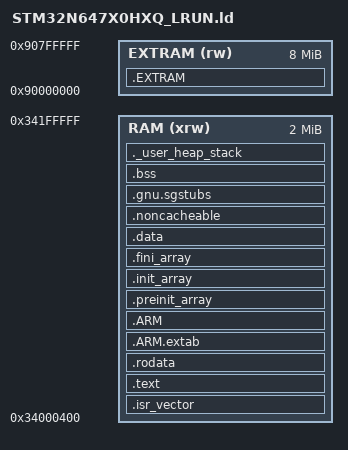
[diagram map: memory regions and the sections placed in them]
/*
******************************************************************************
** @file        : STM32N647X0HXQ_LRUN.ld
** @brief       : Linker script for STM32N647 - LRUN with HyperRAM (XSPI1)
**                Code in internal RAM, framebuffer in HyperRAM
******************************************************************************
*/

/* Entry Point */
ENTRY(Reset_Handler)

/* Highest address of the user mode stack */
_estack = ORIGIN(RAM) + LENGTH(RAM);
_sstack = _estack - _Min_Stack_Size;

_Min_Heap_Size = 0x200;
_Min_Stack_Size = 0x800;

/* Memories definition */
MEMORY
{
  RAM    (xrw)    : ORIGIN = 0x34000400,   LENGTH = 2047K
  EXTRAM (rw)     : ORIGIN = 0x90000000,   LENGTH = 8M
}

/* Sections */
SECTIONS
{
  .isr_vector :
  {
    . = ALIGN(4);
    KEEP(*(.isr_vector))
    . = ALIGN(4);
  } >RAM

  .text :
  {
    . = ALIGN(4);
    *(.text)
    *(.text*)
    *(.glue_7)
    *(.glue_7t)
    *(.eh_frame)
    *(.RamFunc)
    *(.RamFunc*)

    KEEP (*(.init))
    KEEP (*(.fini))

    . = ALIGN(4);
    _etext = .;
  } >RAM

  .rodata :
  {
    . = ALIGN(4);
    *(.rodata)
    *(.rodata*)
    . = ALIGN(4);
  } >RAM

  .ARM.extab   (READONLY) :
  {
    . = ALIGN(4);
    *(.ARM.extab* .gnu.linkonce.armextab.*)
    . = ALIGN(4);
  } >RAM

  .ARM (READONLY) :
  {
    . = ALIGN(4);
    __exidx_start = .;
    *(.ARM.exidx*)
    __exidx_end = .;
    . = ALIGN(4);
  } >RAM

  .preinit_array (READONLY) :
  {
    . = ALIGN(4);
    PROVIDE_HIDDEN (__preinit_array_start = .);
    KEEP (*(.preinit_array*))
    PROVIDE_HIDDEN (__preinit_array_end = .);
    . = ALIGN(4);
  } >RAM

  .init_array (READONLY) :
  {
    . = ALIGN(4);
    PROVIDE_HIDDEN (__init_array_start = .);
    KEEP (*(SORT(.init_array.*)))
    KEEP (*(.init_array*))
    PROVIDE_HIDDEN (__init_array_end = .);
    . = ALIGN(4);
  } >RAM

  .fini_array (READONLY) :
  {
    . = ALIGN(4);
    PROVIDE_HIDDEN (__fini_array_start = .);
    KEEP (*(SORT(.fini_array.*)))
    KEEP (*(.fini_array*))
    PROVIDE_HIDDEN (__fini_array_end = .);
    . = ALIGN(4);
  } >RAM

  _sidata = LOADADDR(.data);

  .data :
  {
    . = ALIGN(4);
    _sdata = .;
    *(.data)
    *(.data*)
    . = ALIGN(4);
    _edata = .;
  } >RAM

  .noncacheable :
  {
    . = ALIGN(8);
    __snoncacheable = .;
    KEEP(*(.noncacheable))
    . = ALIGN(8);
    __enoncacheable = .;
  } > RAM

  .gnu.sgstubs :
  {
    . = ALIGN(4);
    *(.gnu.sgstubs*)
    . = ALIGN(4);
  } >RAM

  . = ALIGN(4);
  .bss :
  {
    _sbss = .;
    __bss_start__ = _sbss;
    *(.bss)
    *(.bss*)
    *(COMMON)
    . = ALIGN(4);
    _ebss = .;
    __bss_end__ = _ebss;
  } >RAM

  ._user_heap_stack :
  {
    . = ALIGN(8);
    PROVIDE ( end = . );
    PROVIDE ( _end = . );
    . = . + _Min_Heap_Size;
    . = . + _Min_Stack_Size;
    . = ALIGN(8);
  } >RAM

  /* HyperRAM framebuffer */
  .EXTRAM (NOLOAD) :
  {
    . = ALIGN(8);
    *(.EXTRAM)
    . = ALIGN(8);
  } >EXTRAM

  /DISCARD/ :
  {
    libc.a ( * )
    libm.a ( * )
    libgcc.a ( * )
  }

  .ARM.attributes 0 : { *(.ARM.attributes) }
}
